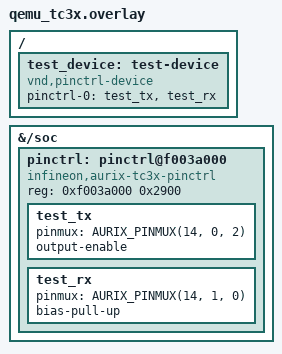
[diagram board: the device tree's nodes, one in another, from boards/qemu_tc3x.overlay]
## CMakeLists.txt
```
# SPDX-FileCopyrightText: Copyright (c) 2024 Infineon Technologies AG,
# SPDX-FileCopyrightText: or an affiliate of Infineon Technologies AG. All rights reserved.
# SPDX-FileCopyrightText: Copyright (c) 2026 Linumiz
#
# SPDX-License-Identifier: Apache-2.0

cmake_minimum_required(VERSION 3.20.0)
find_package(Zephyr REQUIRED HINTS $ENV{ZEPHYR_BASE})
project(infineon_aurix_pinctrl)

target_sources(app PRIVATE src/main.c)
```

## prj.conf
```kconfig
CONFIG_ZTEST=y
CONFIG_PINCTRL=y
```

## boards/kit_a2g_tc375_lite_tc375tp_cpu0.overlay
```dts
/*
 * SPDX-FileCopyrightText: Copyright (c) 2024 Infineon Technologies AG,
 * SPDX-FileCopyrightText: or an affiliate of Infineon Technologies AG. All rights reserved.
 * SPDX-FileCopyrightText: Copyright (c) 2026 Linumiz
 *
 * SPDX-License-Identifier: Apache-2.0
 */

#include <zephyr/dt-bindings/pinctrl/infineon-aurix-pinctrl.h>

/* Same pins as the console, RX with a pull-up */
&pinctrl {
	test_tx: test_tx {
		pinmux = <AURIX_PINMUX(14, 0, 2)>;
		output-enable;
	};

	test_rx: test_rx {
		pinmux = <AURIX_PINMUX(14, 1, 0)>;
		bias-pull-up;
	};
};

/ {
	test_device: test-device {
		compatible = "vnd,pinctrl-device";
		pinctrl-0 = <&test_tx &test_rx>;
		pinctrl-names = "default";
	};
};
```

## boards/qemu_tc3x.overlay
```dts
/*
 * SPDX-FileCopyrightText: Copyright (c) 2024 Infineon Technologies AG,
 * SPDX-FileCopyrightText: or an affiliate of Infineon Technologies AG. All rights reserved.
 * SPDX-FileCopyrightText: Copyright (c) 2026 Linumiz
 *
 * SPDX-License-Identifier: Apache-2.0
 */

#include <zephyr/dt-bindings/pinctrl/infineon-aurix-pinctrl.h>

/* The emulated SoC has no port model; the pin writes have no effect */
&{/soc} {
	pinctrl: pinctrl@f003a000 {
		compatible = "infineon,aurix-tc3x-pinctrl", "infineon,aurix-pinctrl";
		reg = <0xf003a000 0x2900>;

		/* ASCLIN0 TX on P14.0 (ALT2) and RX on P14.1 with a pull-up */
		test_tx: test_tx {
			pinmux = <AURIX_PINMUX(14, 0, 2)>;
			output-enable;
		};

		test_rx: test_rx {
			pinmux = <AURIX_PINMUX(14, 1, 0)>;
			bias-pull-up;
		};
	};
};

/ {
	test_device: test-device {
		compatible = "vnd,pinctrl-device";
		pinctrl-0 = <&test_tx &test_rx>;
		pinctrl-names = "default";
	};
};
```

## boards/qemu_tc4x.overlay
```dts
/*
 * SPDX-FileCopyrightText: Copyright (c) 2024 Infineon Technologies AG,
 * SPDX-FileCopyrightText: or an affiliate of Infineon Technologies AG. All rights reserved.
 * SPDX-FileCopyrightText: Copyright (c) 2026 Linumiz
 *
 * SPDX-License-Identifier: Apache-2.0
 */

#include <zephyr/dt-bindings/pinctrl/infineon-aurix-pinctrl.h>

/* The emulated SoC has no port model; the pin writes have no effect */
&{/soc} {
	pinctrl: pinctrl@f003a000 {
		compatible = "infineon,aurix-tc4x-pinctrl", "infineon,aurix-pinctrl";
		reg = <0xf003a000 0xa400>;

		/* ASCLIN0 TX on P14.0 (ALT2) and RX on P14.1 with a pull-up */
		test_tx: test_tx {
			pinmux = <AURIX_PINMUX(14, 0, 2)>;
			output-enable;
		};

		test_rx: test_rx {
			pinmux = <AURIX_PINMUX(14, 1, 0)>;
			bias-pull-up;
		};
	};
};

/ {
	test_device: test-device {
		compatible = "vnd,pinctrl-device";
		pinctrl-0 = <&test_tx &test_rx>;
		pinctrl-names = "default";
	};
};
```

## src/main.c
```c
/*
 * SPDX-FileCopyrightText: Copyright (c) 2024 Infineon Technologies AG,
 * SPDX-FileCopyrightText: or an affiliate of Infineon Technologies AG. All rights reserved.
 * SPDX-FileCopyrightText: Copyright (c) 2026 Linumiz
 *
 * SPDX-License-Identifier: Apache-2.0
 */

#include <zephyr/drivers/pinctrl.h>
#include <zephyr/ztest.h>

#define TEST_NODE DT_NODELABEL(test_device)

PINCTRL_DT_DEFINE(TEST_NODE);

static const struct pinctrl_dev_config *pcfg = PINCTRL_DT_DEV_CONFIG_GET(TEST_NODE);

ZTEST(aurix_pinctrl, test_state_from_devicetree)
{
	const struct pinctrl_state *state;

	zassert_ok(pinctrl_lookup_state(pcfg, PINCTRL_STATE_DEFAULT, &state));
	zassert_equal(state->pin_cnt, 2);

	zassert_equal(AURIX_PINMUX_PORT(state->pins[0].pinmux), 14);
	zassert_equal(AURIX_PINMUX_PIN(state->pins[0].pinmux), 0);
	zassert_equal(AURIX_PINMUX_FUNC(state->pins[0].pinmux), 2);
	zassert_true(state->pins[0].output);
	zassert_false(state->pins[0].open_drain);

	zassert_equal(AURIX_PINMUX_PORT(state->pins[1].pinmux), 14);
	zassert_equal(AURIX_PINMUX_PIN(state->pins[1].pinmux), 1);
	zassert_false(state->pins[1].output);
	zassert_true(state->pins[1].pull_up);
	zassert_false(state->pins[1].pull_down);
}

ZTEST(aurix_pinctrl, test_apply_state)
{
	zassert_ok(pinctrl_apply_state(pcfg, PINCTRL_STATE_DEFAULT));
}

ZTEST(aurix_pinctrl, test_port_out_of_range)
{
	const pinctrl_soc_pin_t pin = {.pinmux = AURIX_PINMUX(255, 0, 0)};

	zassert_equal(pinctrl_configure_pins(&pin, 1, PINCTRL_REG_NONE), -EINVAL);
}

ZTEST(aurix_pinctrl, test_tc3x_alternate_range)
{
	const pinctrl_soc_pin_t pin = {.pinmux = AURIX_PINMUX(14, 0, 8), .output = 1};

	Z_TEST_SKIP_IFNDEF(CONFIG_PINCTRL_INFINEON_AURIX_TC3X);

	/* TC3x IOCR codes alternate outputs 1 to 7 only */
	zassert_equal(pinctrl_configure_pins(&pin, 1, PINCTRL_REG_NONE), -EINVAL);
}

ZTEST_SUITE(aurix_pinctrl, NULL, NULL, NULL, NULL, NULL);
```
